AUTOSAR XML (schema 4-2-2)
package /AUTOSAR_FiM/PortInterfaces
  client server interface FunctionInhibition: is-service=true
    operation GetFunctionPermission: possible-error=[E_OK, E_NOT_OK]
      arg Permission: type=boolean, direction=OUT
    error E_OK: error-code=0
    error E_NOT_OK: error-code=1
package /AUTOSAR_FiM/SwComponentTypes
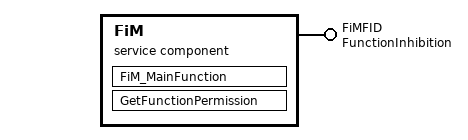
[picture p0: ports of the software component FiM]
  service sw component type FiM
    provide port FiMFID: server-com-spec{operation=GetFunctionPermission, queue-length=1}, provided-interface=FunctionInhibition
    behavior IntBeh_FiM: port-api-option{enable-take-address=false, indirect-api=false, port-defined-argument-value{value=FiMFID:1, value-type=FiM_FunctionIdType}, port=FiMFID}
      operation invoked event RTE_OIEV_GFP_FiMFID: start-on-event=GetFunctionPermission, operation=FiMFID.GetFunctionPermission
      runnable FiM_MainFunction
      runnable GetFunctionPermission: arguments=[symbol=FID, symbol=Permission], can-be-invoked-concurrently=true, symbol=FiM_GetFunctionPermission
package /AUTOSAR_FiM/Implementations
  swc implementation Impl_FiM: programming-language=C, sw-version=9.0.0, swc-bsw-mapping=SwcBswMappings, vendor-id=6, behavior=IntBeh_FiM
    code-descriptors:
      code Impl_FiM_Code: artifact-descriptors=autosar-engineering-object={short-label=FiM_CodeDescription, category=SWSRC}
    resource consumption FiM_ResourceConsumption
      4 x memory section, all with prefix=FIM:
        FIM_VAR_CLEARED: sw-addrmethod=VAR_CLEARED, symbol=VAR_CLEARED
        FIM_VAR_INIT: sw-addrmethod=VAR_INIT, symbol=VAR_INIT
        FIM_CONST: sw-addrmethod=CONST, symbol=CONST
        FIM_CODE: sw-addrmethod=CODE, symbol=CODE
      section name prefix FIM
      section name prefix FiM
package /AUTOSAR_FiM/ImplementationDataTypes
  impl type FiM_FunctionIdType: implementation-data-type=uint16
package /AUTOSAR_FiM/SwcBswMappings
  swc bsw mapping SwcBswMappings: bsw-behavior=IB_FiM, swc-bsw-runnable-mapping{bsw-entity=BSWSE_FiMMainFunction, swc-runnable=FiM_MainFunction}, swc-behavior=IntBeh_FiM
